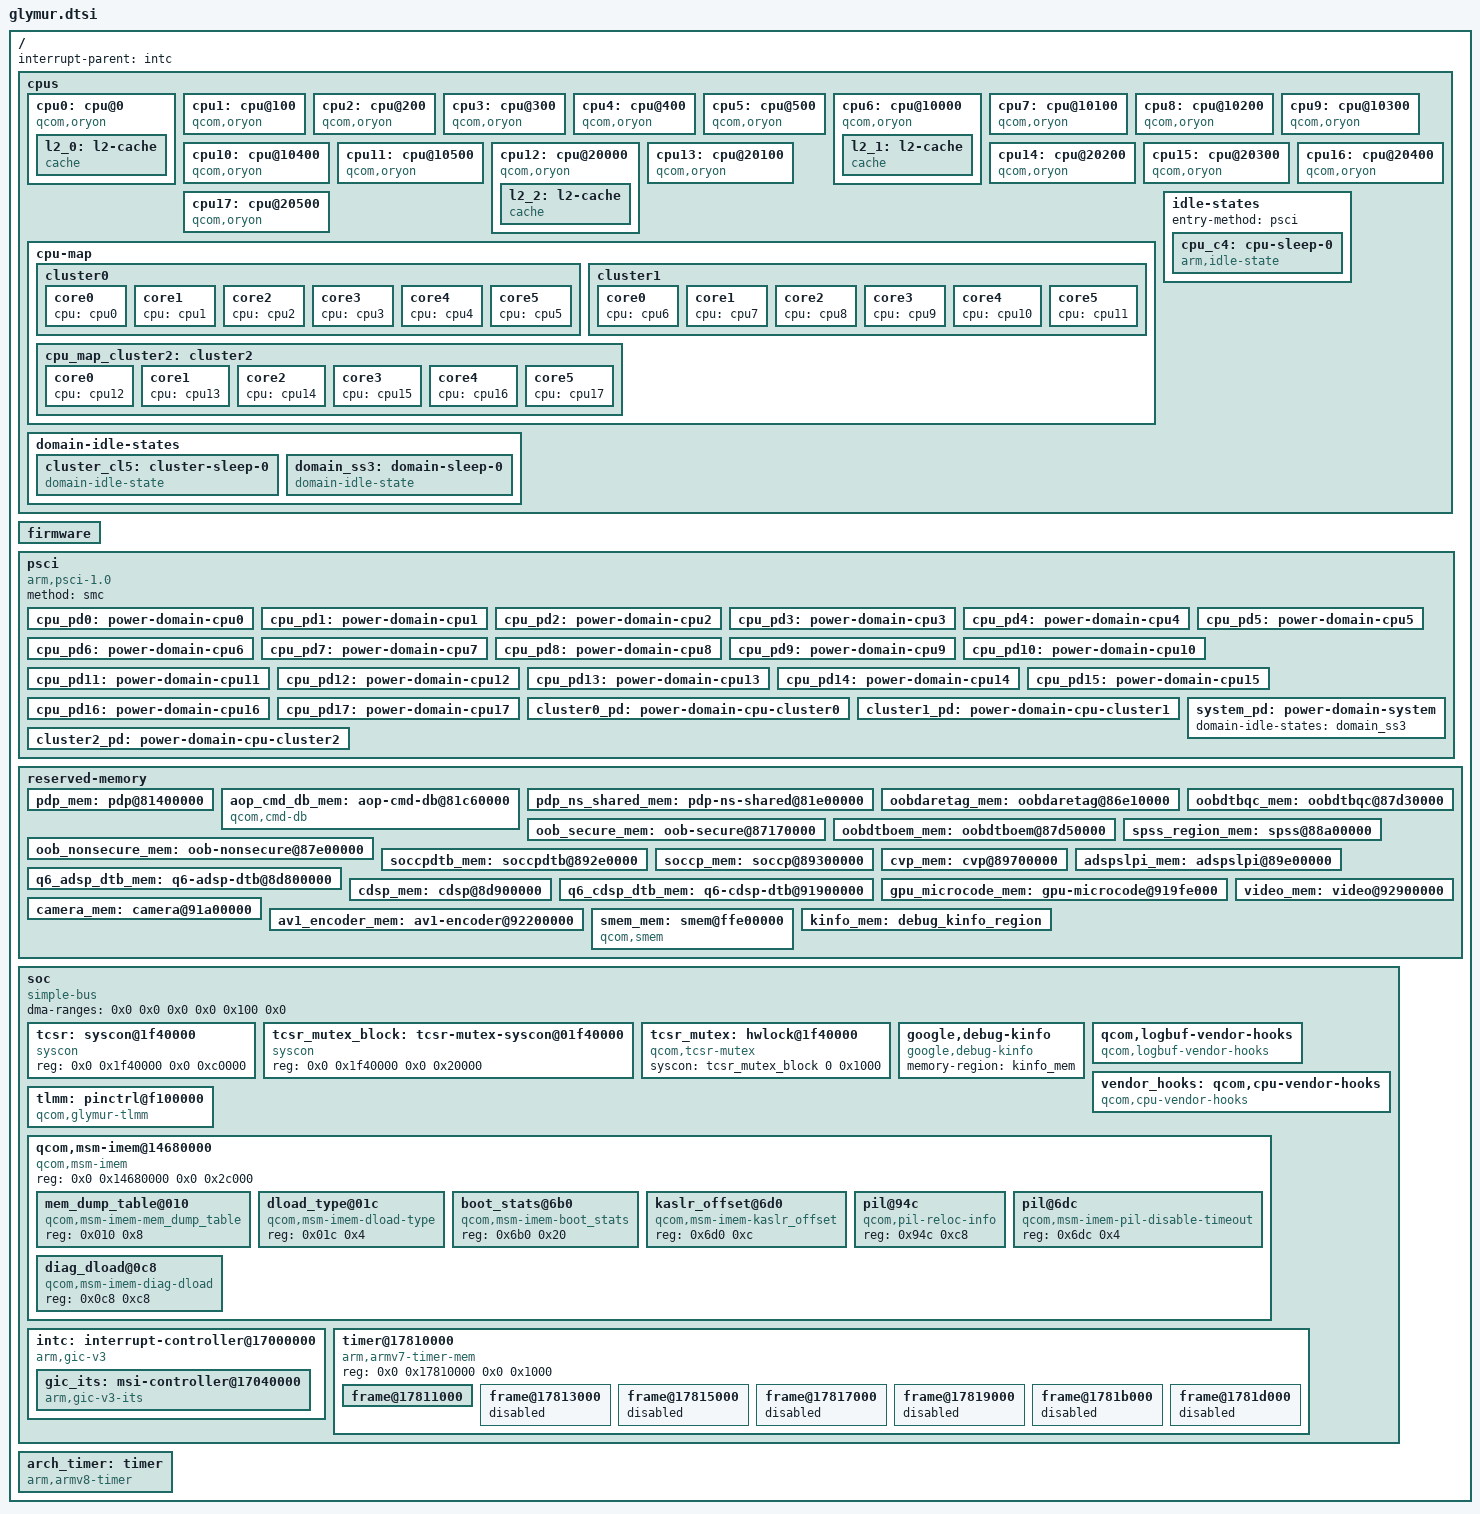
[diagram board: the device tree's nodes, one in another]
// SPDX-License-Identifier: BSD-3-Clause
/*
 * Copyright (c) Qualcomm Technologies, Inc. and/or its subsidiaries.
 */

#include <dt-bindings/interrupt-controller/arm-gic.h>

/ {
	interrupt-parent = <&intc>;
	#address-cells = <2>;
	#size-cells = <2>;

	cpus {
		#address-cells = <2>;
		#size-cells = <0>;

		cpu0: cpu@0 {
			device_type = "cpu";
			compatible = "qcom,oryon";
			reg = <0x0 0x0>;
			enable-method = "psci";
			next-level-cache = <&l2_0>;

			l2_0: l2-cache {
				compatible = "cache";
				cache-level = <2>;
				cache-unified;
			};
		};

		cpu1: cpu@100 {
			device_type = "cpu";
			compatible = "qcom,oryon";
			reg = <0x0 0x100>;
			enable-method = "psci";
			next-level-cache = <&l2_0>;
		};

		cpu2: cpu@200 {
			device_type = "cpu";
			compatible = "qcom,oryon";
			reg = <0x0 0x200>;
			enable-method = "psci";
			next-level-cache = <&l2_0>;
		};

		cpu3: cpu@300 {
			device_type = "cpu";
			compatible = "qcom,oryon";
			reg = <0x0 0x300>;
			enable-method = "psci";
			next-level-cache = <&l2_0>;
		};

		cpu4: cpu@400 {
			device_type = "cpu";
			compatible = "qcom,oryon";
			reg = <0x0 0x400>;
			enable-method = "psci";
			next-level-cache = <&l2_0>;
		};

		cpu5: cpu@500 {
			device_type = "cpu";
			compatible = "qcom,oryon";
			reg = <0x0 0x500>;
			enable-method = "psci";
			next-level-cache = <&l2_0>;
		};

		cpu6: cpu@10000 {
			device_type = "cpu";
			compatible = "qcom,oryon";
			reg = <0x0 0x10000>;
			enable-method = "psci";
			next-level-cache = <&l2_1>;

			l2_1: l2-cache {
				compatible = "cache";
				cache-level = <2>;
				cache-unified;
			};
		};

		cpu7: cpu@10100 {
			device_type = "cpu";
			compatible = "qcom,oryon";
			reg = <0x0 0x10100>;
			enable-method = "psci";
			next-level-cache = <&l2_1>;
		};

		cpu8: cpu@10200 {
			device_type = "cpu";
			compatible = "qcom,oryon";
			reg = <0x0 0x10200>;
			enable-method = "psci";
			next-level-cache = <&l2_1>;
		};

		cpu9: cpu@10300 {
			device_type = "cpu";
			compatible = "qcom,oryon";
			reg = <0x0 0x10300>;
			enable-method = "psci";
			next-level-cache = <&l2_1>;
		};

		cpu10: cpu@10400 {
			device_type = "cpu";
			compatible = "qcom,oryon";
			reg = <0x0 0x10400>;
			enable-method = "psci";
			next-level-cache = <&l2_1>;
		};

		cpu11: cpu@10500 {
			device_type = "cpu";
			compatible = "qcom,oryon";
			reg = <0x0 0x10500>;
			enable-method = "psci";
			next-level-cache = <&l2_1>;
		};

		cpu12: cpu@20000 {
			device_type = "cpu";
			compatible = "qcom,oryon";
			reg = <0x0 0x20000>;
			enable-method = "psci";
			next-level-cache = <&l2_2>;

			l2_2: l2-cache {
				compatible = "cache";
				cache-level = <2>;
				cache-unified;
			};
		};

		cpu13: cpu@20100 {
			device_type = "cpu";
			compatible = "qcom,oryon";
			reg = <0x0 0x20100>;
			enable-method = "psci";
			next-level-cache = <&l2_2>;
		};

		cpu14: cpu@20200 {
			device_type = "cpu";
			compatible = "qcom,oryon";
			reg = <0x0 0x20200>;
			enable-method = "psci";
			next-level-cache = <&l2_2>;
		};

		cpu15: cpu@20300 {
			device_type = "cpu";
			compatible = "qcom,oryon";
			reg = <0x0 0x20300>;
			enable-method = "psci";
			next-level-cache = <&l2_2>;
		};

		cpu16: cpu@20400 {
			device_type = "cpu";
			compatible = "qcom,oryon";
			reg = <0x0 0x20400>;
			enable-method = "psci";
			next-level-cache = <&l2_2>;
		};

		cpu17: cpu@20500 {
			device_type = "cpu";
			compatible = "qcom,oryon";
			reg = <0x0 0x20500>;
			enable-method = "psci";
			next-level-cache = <&l2_2>;
		};

		cpu-map {
			cluster0 {
				core0 {
					cpu = <&cpu0>;
				};

				core1 {
					cpu = <&cpu1>;
				};

				core2 {
					cpu = <&cpu2>;
				};

				core3 {
					cpu = <&cpu3>;
				};

				core4 {
					cpu = <&cpu4>;
				};

				core5 {
					cpu = <&cpu5>;
				};
			};

			cluster1 {
				core0 {
					cpu = <&cpu6>;
				};

				core1 {
					cpu = <&cpu7>;
				};

				core2 {
					cpu = <&cpu8>;
				};

				core3 {
					cpu = <&cpu9>;
				};

				core4 {
					cpu = <&cpu10>;
				};

				core5 {
					cpu = <&cpu11>;
				};
			};

			cpu_map_cluster2: cluster2 {
				core0 {
					cpu = <&cpu12>;
				};

				core1 {
					cpu = <&cpu13>;
				};

				core2 {
					cpu = <&cpu14>;
				};

				core3 {
					cpu = <&cpu15>;
				};

				core4 {
					cpu = <&cpu16>;
				};

				core5 {
					cpu = <&cpu17>;
				};
			};
		};

		idle-states {
			entry-method = "psci";

			cpu_c4: cpu-sleep-0 {
				compatible = "arm,idle-state";
				idle-state-name = "ret";
				arm,psci-suspend-param = <0x00000004>;
				entry-latency-us = <180>;
				exit-latency-us = <320>;
				min-residency-us = <1000>;
			};
		};

		domain-idle-states {
			cluster_cl5: cluster-sleep-0 {
				compatible = "domain-idle-state";
				arm,psci-suspend-param = <0x01000054>;
				entry-latency-us = <2000>;
				exit-latency-us = <2000>;
				min-residency-us = <9000>;
			};

			domain_ss3: domain-sleep-0 {
				compatible = "domain-idle-state";
				arm,psci-suspend-param = <0x0200c354>;
				entry-latency-us = <2800>;
				exit-latency-us = <4400>;
				min-residency-us = <10150>;
			};
		};
	};

	firmware {

	};

	psci {
		compatible = "arm,psci-1.0";
		method = "smc";

		cpu_pd0: power-domain-cpu0 {
			#power-domain-cells = <0>;
			power-domains = <&cluster0_pd>;
			domain-idle-states = <&cpu_c4>;
		};

		cpu_pd1: power-domain-cpu1 {
			#power-domain-cells = <0>;
			power-domains = <&cluster0_pd>;
			domain-idle-states = <&cpu_c4>;
		};

		cpu_pd2: power-domain-cpu2 {
			#power-domain-cells = <0>;
			power-domains = <&cluster0_pd>;
			domain-idle-states = <&cpu_c4>;
		};

		cpu_pd3: power-domain-cpu3 {
			#power-domain-cells = <0>;
			power-domains = <&cluster0_pd>;
			domain-idle-states = <&cpu_c4>;
		};

		cpu_pd4: power-domain-cpu4 {
			#power-domain-cells = <0>;
			power-domains = <&cluster0_pd>;
			domain-idle-states = <&cpu_c4>;
		};

		cpu_pd5: power-domain-cpu5 {
			#power-domain-cells = <0>;
			power-domains = <&cluster0_pd>;
			domain-idle-states = <&cpu_c4>;
		};

		cpu_pd6: power-domain-cpu6 {
			#power-domain-cells = <0>;
			power-domains = <&cluster1_pd>;
			domain-idle-states = <&cpu_c4>;
		};

		cpu_pd7: power-domain-cpu7 {
			#power-domain-cells = <0>;
			power-domains = <&cluster1_pd>;
			domain-idle-states = <&cpu_c4>;
		};

		cpu_pd8: power-domain-cpu8 {
			#power-domain-cells = <0>;
			power-domains = <&cluster1_pd>;
			domain-idle-states = <&cpu_c4>;
		};

		cpu_pd9: power-domain-cpu9 {
			#power-domain-cells = <0>;
			power-domains = <&cluster1_pd>;
			domain-idle-states = <&cpu_c4>;
		};

		cpu_pd10: power-domain-cpu10 {
			#power-domain-cells = <0>;
			power-domains = <&cluster1_pd>;
			domain-idle-states = <&cpu_c4>;
		};

		cpu_pd11: power-domain-cpu11 {
			#power-domain-cells = <0>;
			power-domains = <&cluster1_pd>;
			domain-idle-states = <&cpu_c4>;
		};

		cpu_pd12: power-domain-cpu12 {
			#power-domain-cells = <0>;
			power-domains = <&cluster2_pd>;
			domain-idle-states = <&cpu_c4>;
		};

		cpu_pd13: power-domain-cpu13 {
			#power-domain-cells = <0>;
			power-domains = <&cluster2_pd>;
			domain-idle-states = <&cpu_c4>;
		};

		cpu_pd14: power-domain-cpu14 {
			#power-domain-cells = <0>;
			power-domains = <&cluster2_pd>;
			domain-idle-states = <&cpu_c4>;
		};

		cpu_pd15: power-domain-cpu15 {
			#power-domain-cells = <0>;
			power-domains = <&cluster2_pd>;
			domain-idle-states = <&cpu_c4>;
		};

		cpu_pd16: power-domain-cpu16 {
			#power-domain-cells = <0>;
			power-domains = <&cluster2_pd>;
			domain-idle-states = <&cpu_c4>;
		};

		cpu_pd17: power-domain-cpu17 {
			#power-domain-cells = <0>;
			power-domains = <&cluster2_pd>;
			domain-idle-states = <&cpu_c4>;
		};

		cluster0_pd: power-domain-cpu-cluster0 {
			#power-domain-cells = <0>;
			power-domains = <&system_pd>;
			domain-idle-states = <&cluster_cl5>;
		};

		cluster1_pd: power-domain-cpu-cluster1 {
			#power-domain-cells = <0>;
			power-domains = <&system_pd>;
			domain-idle-states = <&cluster_cl5>;
		};

		cluster2_pd: power-domain-cpu-cluster2 {
			#power-domain-cells = <0>;
			power-domains = <&system_pd>;
			domain-idle-states = <&cluster_cl5>;
		};

		system_pd: power-domain-system {
			#power-domain-cells = <0>;
			domain-idle-states = <&domain_ss3>;
		};
	};

	reserved-memory {
		#address-cells = <2>;
		#size-cells = <2>;
		ranges;

		pdp_mem: pdp@81400000 {
			reg = <0x0 0x81400000 0x0 0x100000>;
			no-map;
		};

		aop_cmd_db_mem: aop-cmd-db@81c60000 {
			compatible = "qcom,cmd-db";
			reg = <0x0 0x81c60000 0x0 0x20000>;
			no-map;
		};

		pdp_ns_shared_mem: pdp-ns-shared@81e00000 {
			reg = <0x0 0x81e00000 0x0 0x200000>;
			no-map;
		};

		oobdaretag_mem: oobdaretag@86e10000 {
			reg = <0x0 0x86e10000 0x0 0x360000>;
			no-map;
		};

		oob_secure_mem: oob-secure@87170000 {
			reg = <0x0 0x87170000 0x0 0xbc0000>;
			no-map;
		};

		oobdtbqc_mem: oobdtbqc@87d30000 {
			reg = <0x0 0x87d30000 0x0 0x20000>;
			no-map;
		};

		oobdtboem_mem: oobdtboem@87d50000 {
			reg = <0x0 0x87d50000 0x0 0x20000>;
			no-map;
		};

		oob_nonsecure_mem: oob-nonsecure@87e00000 {
			reg = <0x0 0x87e00000 0x0 0xc00000>;
			no-map;
		};

		spss_region_mem: spss@88a00000 {
			reg = <0x0 0x88a00000 0x0 0x400000>;
			no-map;
		};

		soccpdtb_mem: soccpdtb@892e0000 {
			reg = <0x0 0x892e0000 0x0 0x20000>;
			no-map;
		};

		soccp_mem: soccp@89300000 {
			reg = <0x0 0x89300000 0x0 0x400000>;
			no-map;
		};

		cvp_mem: cvp@89700000 {
			reg = <0x0 0x89700000 0x0 0x700000>;
			no-map;
		};

		adspslpi_mem: adspslpi@89e00000 {
			reg = <0x0 0x89e00000 0x0 0x3a00000>;
			no-map;
		};

		q6_adsp_dtb_mem: q6-adsp-dtb@8d800000 {
			reg = <0x0 0x8d800000 0x0 0x80000>;
			no-map;
		};

		cdsp_mem: cdsp@8d900000 {
			reg = <0x0 0x8d900000 0x0 0x4000000>;
			no-map;
		};

		q6_cdsp_dtb_mem: q6-cdsp-dtb@91900000 {
			reg = <0x0 0x91900000 0x0 0x80000>;
			no-map;
		};

		gpu_microcode_mem: gpu-microcode@919fe000 {
			reg = <0x0 0x919fe000 0x0 0x2000>;
			no-map;
		};

		camera_mem: camera@91a00000 {
			reg = <0x0 0x91a00000 0x0 0x800000>;
			no-map;
		};

		av1_encoder_mem: av1-encoder@92200000 {
			reg = <0x0 0x92200000 0x0 0x700000>;
			no-map;
		};

		video_mem: video@92900000 {
			reg = <0x0 0x92900000 0x0 0xc00000>;
			no-map;
		};

		smem_mem: smem@ffe00000 {
			compatible = "qcom,smem";
			reg = <0x0 0xffe00000 0x0 0x200000>;
			hwlocks = <&tcsr_mutex 3>;
			no-map;
		};

		kinfo_mem: debug_kinfo_region {
			alloc-ranges = <0x0 0x00000000 0xffffffff 0xffffffff>;
			size = <0x0 0x1000>;
			no-map;
		};
	};

	soc: soc {
		compatible = "simple-bus";
		#address-cells = <2>;
		#size-cells = <2>;
		ranges = <0x0 0x0 0x0 0x0 0x100 0x0>;
		dma-ranges = <0x0 0x0 0x0 0x0 0x100 0x0>;

		tcsr: syscon@1f40000 {
			compatible = "syscon";
			reg = <0x0 0x1f40000 0x0 0xc0000>;
		};

		tcsr_mutex_block: tcsr-mutex-syscon@01f40000 {
			compatible = "syscon";
			reg = <0x0 0x1f40000 0x0 0x20000>;
		};

		tcsr_mutex: hwlock@1f40000 {
			compatible = "qcom,tcsr-mutex";
			syscon  = <&tcsr_mutex_block 0 0x1000>;
			#hwlock-cells = <1>;
		};

		google,debug-kinfo {
			compatible = "google,debug-kinfo";
			memory-region = <&kinfo_mem>;
		};

		qcom,logbuf-vendor-hooks {
			compatible = "qcom,logbuf-vendor-hooks";
		};

		vendor_hooks: qcom,cpu-vendor-hooks {
			compatible = "qcom,cpu-vendor-hooks";
		};

		tlmm: pinctrl@f100000 {
			compatible = "qcom,glymur-tlmm";
			reg = <0x0 0x0f100000 0x0 0xf00000>;
			interrupts = <GIC_SPI 208 IRQ_TYPE_LEVEL_HIGH>;
			gpio-controller;
			#gpio-cells = <2>;
			interrupt-controller;
			#interrupt-cells = <2>;
			gpio-ranges = <&tlmm 0 0 249>;
		};

		qcom,msm-imem@14680000 {
			compatible = "qcom,msm-imem";
			reg = <0x0 0x14680000 0x0 0x2c000>;
			ranges = <0x0 0x0 0x14680000 0x2c000>;
			#address-cells = <1>;
			#size-cells = <1>;

			mem_dump_table@010 {
				compatible = "qcom,msm-imem-mem_dump_table";
				reg = <0x010 0x8>;
			};

			dload_type@01c {
				compatible = "qcom,msm-imem-dload-type";
				reg = <0x01c 0x4>;
			};

			boot_stats@6b0 {
				compatible = "qcom,msm-imem-boot_stats";
				reg = <0x6b0 0x20>;
			};

			kaslr_offset@6d0 {
				compatible = "qcom,msm-imem-kaslr_offset";
				reg = <0x6d0 0xc>;
			};

			pil@94c {
				compatible = "qcom,pil-reloc-info";
				reg = <0x94c 0xc8>;
			};

			pil@6dc {
				compatible = "qcom,msm-imem-pil-disable-timeout";
				reg = <0x6dc 0x4>;
			};

			diag_dload@0c8 {
				compatible = "qcom,msm-imem-diag-dload";
				reg = <0x0c8 0xc8>;
			};
		};

		intc: interrupt-controller@17000000 {
			compatible = "arm,gic-v3";
			reg = <0x0 0x17000000 0x0 0x10000>,
			      <0x0 0x17080000 0x0 0x480000>;
			interrupts = <GIC_PPI 9 IRQ_TYPE_LEVEL_HIGH>;
			#interrupt-cells = <3>;
			interrupt-controller;
			#address-cells = <2>;
			#size-cells = <2>;
			ranges;

			gic_its: msi-controller@17040000 {
				compatible = "arm,gic-v3-its";
				reg = <0x0 0x17040000 0x0 0x40000>;
				msi-controller;
				#msi-cells = <1>;
			};
		};

		timer@17810000 {
			compatible = "arm,armv7-timer-mem";
			reg = <0x0 0x17810000 0x0 0x1000>;
			#address-cells = <2>;
			#size-cells = <1>;
			ranges = <0x0 0x0 0x0 0x0 0x20000000>;

			frame@17811000 {
				reg = <0x0 0x17811000 0x1000>,
				      <0x0 0x17812000 0x1000>;
				interrupts = <GIC_SPI 8 IRQ_TYPE_LEVEL_HIGH>,
					     <GIC_SPI 6 IRQ_TYPE_LEVEL_HIGH>;
				frame-number = <0>;
			};

			frame@17813000 {
				reg = <0x0 0x17813000 0x1000>;
				interrupts = <GIC_SPI 9 IRQ_TYPE_LEVEL_HIGH>;
				frame-number = <1>;
				status = "disabled";
			};

			frame@17815000 {
				reg = <0x0 0x17815000 0x1000>;
				interrupts = <GIC_SPI 10 IRQ_TYPE_LEVEL_HIGH>;
				frame-number = <2>;
				status = "disabled";
			};

			frame@17817000 {
				reg = <0x0 0x17817000 0x1000>;
				interrupts = <GIC_SPI 11 IRQ_TYPE_LEVEL_HIGH>;
				frame-number = <3>;
				status = "disabled";
			};

			frame@17819000 {
				reg = <0x0 0x17819000 0x1000>;
				interrupts = <GIC_SPI 12 IRQ_TYPE_LEVEL_HIGH>;
				frame-number = <4>;
				status = "disabled";
			};

			frame@1781b000 {
				reg = <0x0 0x1781b000 0x1000>;
				interrupts = <GIC_SPI 13 IRQ_TYPE_LEVEL_HIGH>;
				frame-number = <5>;
				status = "disabled";
			};

			frame@1781d000 {
				reg = <0x0 0x1781d000 0x1000>;
				interrupts = <GIC_SPI 14 IRQ_TYPE_LEVEL_HIGH>;
				frame-number = <6>;
				status = "disabled";
			};
		};
	};

	arch_timer: timer {
		compatible = "arm,armv8-timer";
		interrupts = <GIC_PPI 13 IRQ_TYPE_LEVEL_LOW>,
			     <GIC_PPI 14 IRQ_TYPE_LEVEL_LOW>,
			     <GIC_PPI 11 IRQ_TYPE_LEVEL_LOW>,
			     <GIC_PPI 10 IRQ_TYPE_LEVEL_LOW>,
			     <GIC_PPI 12 IRQ_TYPE_LEVEL_LOW>;
	};
};

#include "glymur-pinctrl.dtsi"
